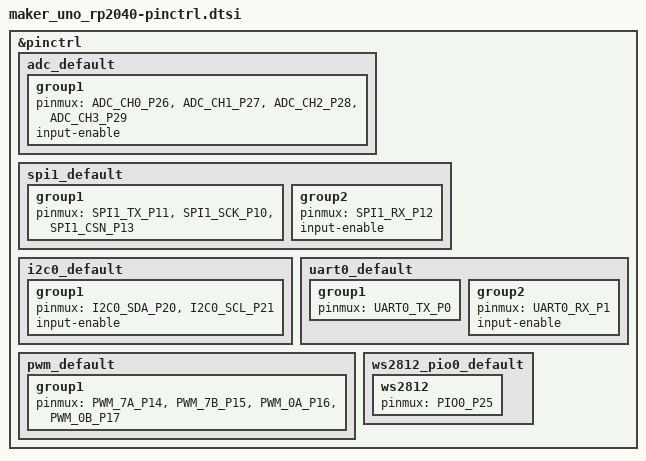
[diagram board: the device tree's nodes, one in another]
/*
 * Copyright (c) 2025 Jonas Berg
 *
 * SPDX-License-Identifier: Apache-2.0
 */

#include <zephyr/dt-bindings/pinctrl/rpi-pico-rp2040-pinctrl.h>

&pinctrl {
	adc_default: adc_default {
		group1 {
			pinmux = <ADC_CH0_P26>, <ADC_CH1_P27>, <ADC_CH2_P28>, <ADC_CH3_P29>;
			input-enable;
		};
	};

	spi1_default: spi1_default {
		group1 {
			pinmux = <SPI1_TX_P11>, <SPI1_SCK_P10>, <SPI1_CSN_P13>;
		};

		group2 {
			pinmux = <SPI1_RX_P12>;
			input-enable;
		};
	};

	i2c0_default: i2c0_default {
		group1 {
			pinmux = <I2C0_SDA_P20>, <I2C0_SCL_P21>;
			input-enable;
		};
	};

	uart0_default: uart0_default {
		group1 {
			pinmux = <UART0_TX_P0>;
		};

		group2 {
			pinmux = <UART0_RX_P1>;
			input-enable;
		};
	};

	pwm_default: pwm_default {
		group1 {
			pinmux = <PWM_7A_P14>, <PWM_7B_P15>, <PWM_0A_P16>, <PWM_0B_P17>;
		};
	};

	ws2812_pio0_default: ws2812_pio0_default {
		ws2812 {
			pinmux = <PIO0_P25>;
		};
	};
};
